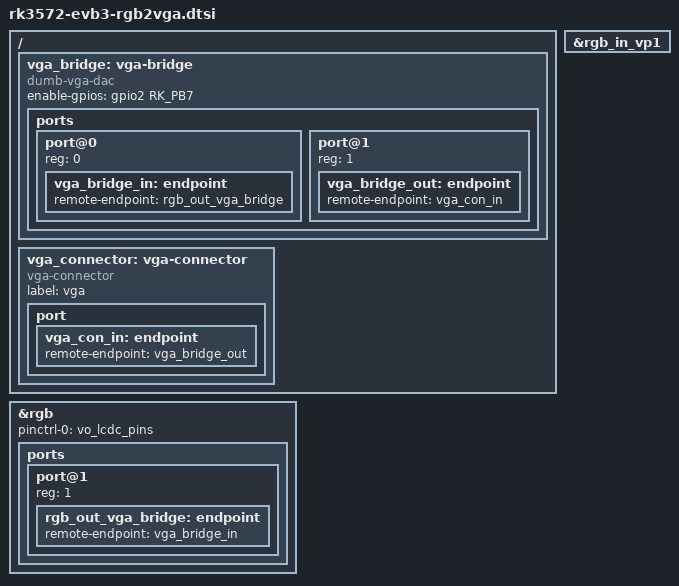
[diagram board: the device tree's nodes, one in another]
// SPDX-License-Identifier: (GPL-2.0+ OR MIT)
/*
 * Copyright (c) 2026 Rockchip Electronics Co., Ltd.
 */

#include <dt-bindings/display/media-bus-format.h>

/ {
	vga_bridge: vga-bridge {
		compatible = "dumb-vga-dac";
		enable-gpios = <&gpio2 RK_PB7 GPIO_ACTIVE_HIGH>;

		ports {
			#address-cells = <1>;
			#size-cells = <0>;

			port@0 {
				reg = <0>;

				vga_bridge_in: endpoint {
					remote-endpoint = <&rgb_out_vga_bridge>;
				};
			};

			port@1 {
				reg = <1>;

				vga_bridge_out: endpoint {
					remote-endpoint = <&vga_con_in>;
				};
			};
		};
	};

	vga_connector: vga-connector {
		compatible = "vga-connector";
		label = "vga";

		port {
			vga_con_in: endpoint {
				remote-endpoint = <&vga_bridge_out>;
			};
		};
	};
};

&rgb {
	status = "okay";
	pinctrl-names = "default";
	pinctrl-0 = <&vo_lcdc_pins>;

	ports {
		port@1 {
			reg = <1>;

			rgb_out_vga_bridge: endpoint {
				remote-endpoint = <&vga_bridge_in>;
			};
		};
	};
};

&rgb_in_vp1 {
	status = "okay";
};
